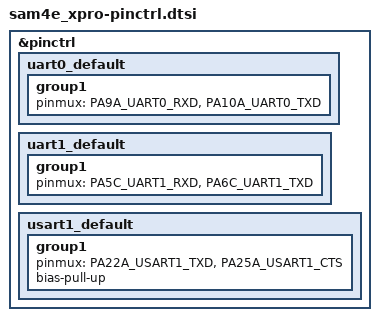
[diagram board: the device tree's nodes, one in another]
/*
 * Copyright (c) 2022, Gerson Fernando Budke <nandojve@gmail.com>
 * SPDX-License-Identifier: Apache-2.0
 */

#include <dt-bindings/pinctrl/sam4eXe-pinctrl.h>

&pinctrl {
	uart0_default: uart0_default {
		group1 {
			pinmux = <PA9A_UART0_RXD>,
				 <PA10A_UART0_TXD>;
		};
	};
	uart1_default: uart1_default {
		group1 {
			pinmux = <PA5C_UART1_RXD>,
				 <PA6C_UART1_TXD>;
		};
	};
	usart1_default: usart1_default {
		group1 {
			pinmux = <PA21A_USART1_RXD>,
				 <PA24A_USART1_RTS>;
			bias-pull-up;
		};
		group1 {
			pinmux = <PA22A_USART1_TXD>,
				 <PA25A_USART1_CTS>;
		};
	};
};
